# STM32F733ZET7 register map
File version: 1.0
Registers are 32-bit, access not given, reset 0x0 unless marked. A register's access mark holds for its fields unless they carry their own. Offsets are from the block's base; [hi:lo] are bit positions; {n}, {i} and the like mark numbered series; 'fields as' and 'values as' point back to an identical list.

## CRC
Base 0x40023000
0x00 DR
0x04 IDR 8-bit
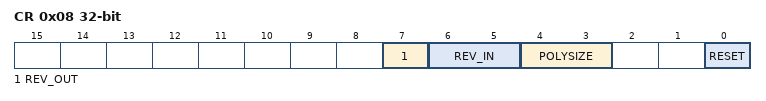
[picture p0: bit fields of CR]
0x08 CR
  [7] REV_OUT, [6:5] REV_IN, [4:3] POLYSIZE, [0] RESET
0x10 INIT
0x14 POL

## FLASH
Base 0x40023C00
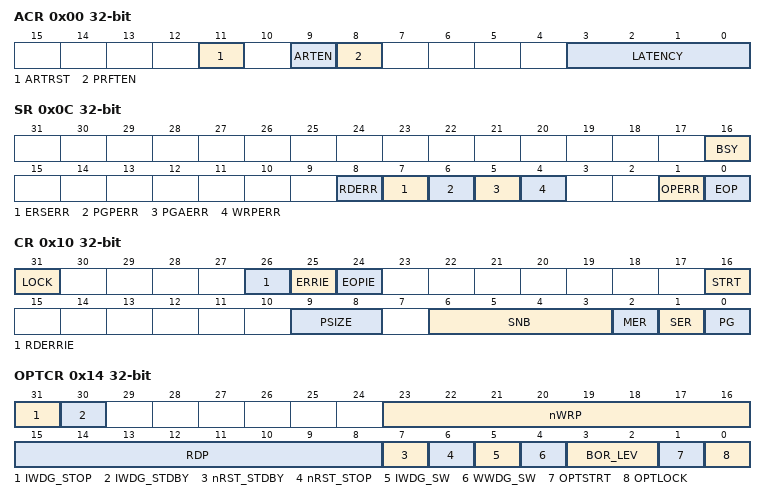
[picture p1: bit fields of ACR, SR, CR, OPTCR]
0x00 ACR
  [11] ARTRST, [9] ARTEN, [8] PRFTEN, [3:0] LATENCY
0x04 KEYR
0x08 OPTKEYR
0x0C SR
  [16] BSY, [8] RDERR, [7] ERSERR, [6] PGPERR, [5] PGAERR, [4] WRPERR, [1] OPERR, [0] EOP
0x10 CR
  [31] LOCK, [26] RDERRIE, [25] ERRIE, [24] EOPIE, [16] STRT, [9:8] PSIZE, [6:3] SNB, [2] MER, [1] SER, [0] PG
0x14 OPTCR
  [31] IWDG_STOP, [30] IWDG_STDBY, [23:16] nWRP, [15:8] RDP, [7] nRST_STDBY, [6] nRST_STOP, [5] IWDG_SW, [4] WWDG_SW, [3:2] BOR_LEV, [1] OPTSTRT, [0] OPTLOCK
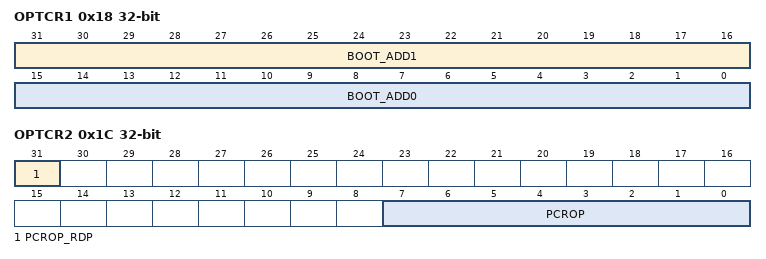
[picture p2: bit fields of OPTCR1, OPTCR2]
0x18 OPTCR1
  [31:16] BOOT_ADD1, [15:0] BOOT_ADD0
0x1C OPTCR2
  [31] PCROP_RDP, [7:0] PCROP

## DMA1
Base 0x40026000
Same registers: DMA2 0x40026400
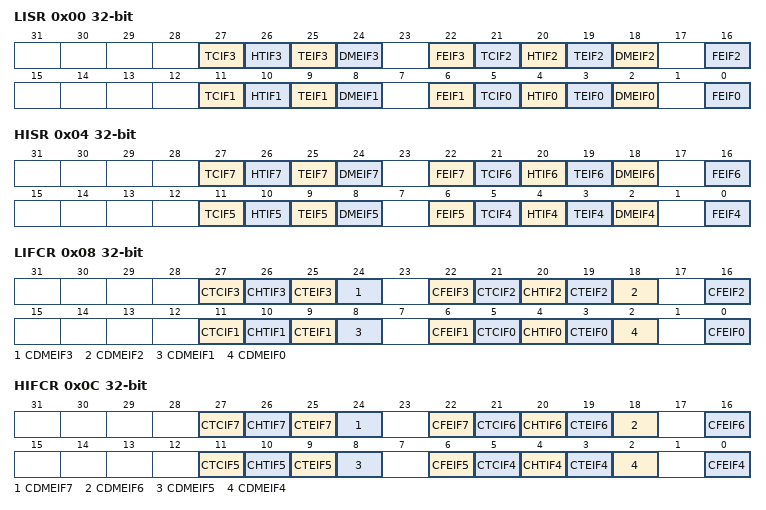
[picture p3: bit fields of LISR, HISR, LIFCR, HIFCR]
0x00 LISR
  [27] TCIF3, [26] HTIF3, [25] TEIF3, [24] DMEIF3, [22] FEIF3, [21] TCIF2, [20] HTIF2, [19] TEIF2, [18] DMEIF2, [16] FEIF2, [11] TCIF1, [10] HTIF1, [9] TEIF1, [8] DMEIF1, [6] FEIF1, [5] TCIF0, [4] HTIF0, [3] TEIF0, [2] DMEIF0, [0] FEIF0
0x04 HISR
  [27] TCIF7, [26] HTIF7, [25] TEIF7, [24] DMEIF7, [22] FEIF7, [21] TCIF6, [20] HTIF6, [19] TEIF6, [18] DMEIF6, [16] FEIF6, [11] TCIF5, [10] HTIF5, [9] TEIF5, [8] DMEIF5, [6] FEIF5, [5] TCIF4, [4] HTIF4, [3] TEIF4, [2] DMEIF4, [0] FEIF4
0x08 LIFCR
  [27] CTCIF3, [26] CHTIF3, [25] CTEIF3, [24] CDMEIF3, [22] CFEIF3, [21] CTCIF2, [20] CHTIF2, [19] CTEIF2, [18] CDMEIF2, [16] CFEIF2, [11] CTCIF1, [10] CHTIF1, [9] CTEIF1, [8] CDMEIF1, [6] CFEIF1, [5] CTCIF0, [4] CHTIF0, [3] CTEIF0, [2] CDMEIF0, [0] CFEIF0
0x0C HIFCR
  [27] CTCIF7, [26] CHTIF7, [25] CTEIF7, [24] CDMEIF7, [22] CFEIF7, [21] CTCIF6, [20] CHTIF6, [19] CTEIF6, [18] CDMEIF6, [16] CFEIF6, [11] CTCIF5, [10] CHTIF5, [9] CTEIF5, [8] CDMEIF5, [6] CFEIF5, [5] CTCIF4, [4] CHTIF4, [3] CTEIF4, [2] CDMEIF4, [0] CFEIF4
{0x10+0x18*i} CR{i} (i=0..7)
{0x14+0x18*i} NDTR{i} (i=0..7)
{0x18+0x18*i} PAR{i} (i=0..7)
{0x1C+0x18*i} M0AR{i} (i=0..7)
{0x20+0x18*i} M1AR{i} (i=0..7)
{0x24+0x18*i} FCR{i} (i=0..7)

## USB_OTG_HS
Base 0x40040000
Same registers: USB_OTG_FS 0x50000000
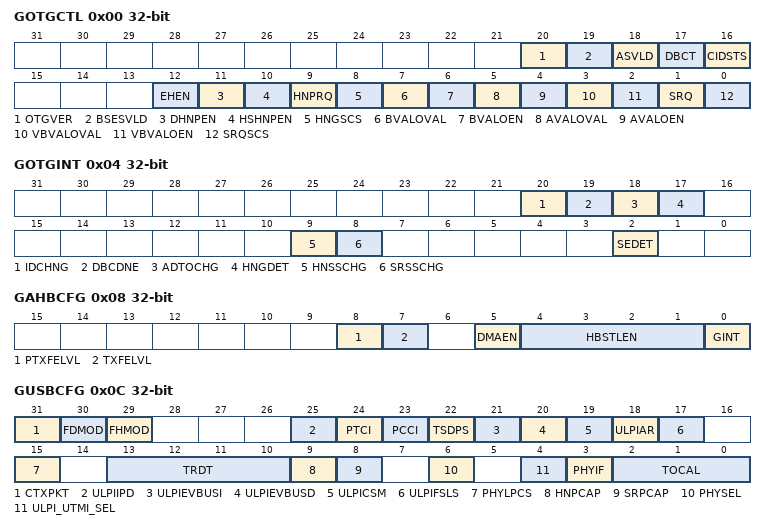
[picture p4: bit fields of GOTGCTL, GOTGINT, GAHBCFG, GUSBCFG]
0x00 GOTGCTL
  [20] OTGVER, [19] BSESVLD, [18] ASVLD, [17] DBCT, [16] CIDSTS, [12] EHEN, [11] DHNPEN, [10] HSHNPEN, [9] HNPRQ, [8] HNGSCS, [7] BVALOVAL, [6] BVALOEN, [5] AVALOVAL, [4] AVALOEN, [3] VBVALOVAL, [2] VBVALOEN, [1] SRQ, [0] SRQSCS
0x04 GOTGINT
  [20] IDCHNG, [19] DBCDNE, [18] ADTOCHG, [17] HNGDET, [9] HNSSCHG, [8] SRSSCHG, [2] SEDET
0x08 GAHBCFG
  [8] PTXFELVL, [7] TXFELVL, [5] DMAEN, [4:1] HBSTLEN, [0] GINT
0x0C GUSBCFG
  [31] CTXPKT, [30] FDMOD, [29] FHMOD, [25] ULPIIPD, [24] PTCI, [23] PCCI, [22] TSDPS, [21] ULPIEVBUSI, [20] ULPIEVBUSD, [19] ULPICSM, [18] ULPIAR, [17] ULPIFSLS, [15] PHYLPCS, [13:10] TRDT, [9] HNPCAP, [8] SRPCAP, [6] PHYSEL, [4] ULPI_UTMI_SEL, [3] PHYIF, [2:0] TOCAL
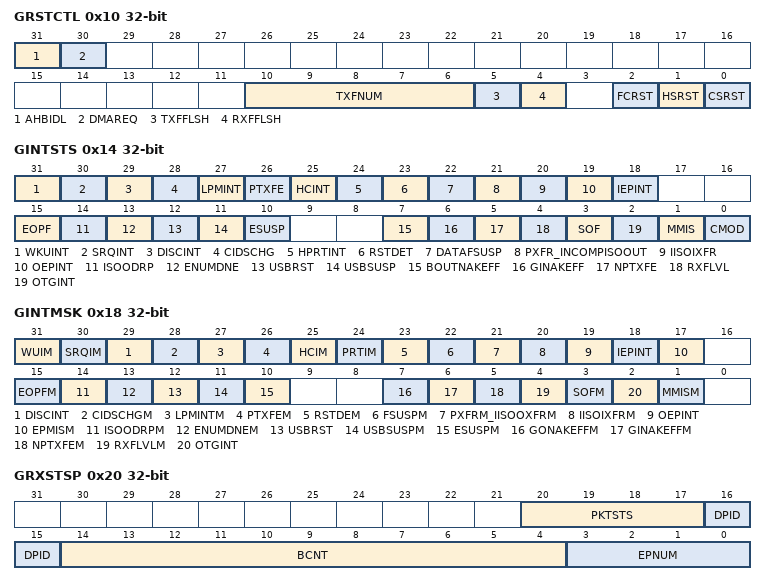
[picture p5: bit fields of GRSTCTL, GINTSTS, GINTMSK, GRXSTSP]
0x10 GRSTCTL
  [31] AHBIDL, [30] DMAREQ, [10:6] TXFNUM, [5] TXFFLSH, [4] RXFFLSH, [2] FCRST, [1] HSRST, [0] CSRST
0x14 GINTSTS
  [31] WKUINT, [30] SRQINT, [29] DISCINT, [28] CIDSCHG, [27] LPMINT, [26] PTXFE, [25] HCINT, [24] HPRTINT, [23] RSTDET, [22] DATAFSUSP, [21] PXFR_INCOMPISOOUT, [20] IISOIXFR, [19] OEPINT, [18] IEPINT, [15] EOPF, [14] ISOODRP, [13] ENUMDNE, [12] USBRST, [11] USBSUSP, [10] ESUSP, [7] BOUTNAKEFF, [6] GINAKEFF, [5] NPTXFE, [4] RXFLVL, [3] SOF, [2] OTGINT, [1] MMIS, [0] CMOD
0x18 GINTMSK
  [31] WUIM, [30] SRQIM, [29] DISCINT, [28] CIDSCHGM, [27] LPMINTM, [26] PTXFEM, [25] HCIM, [24] PRTIM, [23] RSTDEM, [22] FSUSPM, [21] PXFRM_IISOOXFRM, [20] IISOIXFRM, [19] OEPINT, [18] IEPINT, [17] EPMISM, [15] EOPFM, [14] ISOODRPM, [13] ENUMDNEM, [12] USBRST, [11] USBSUSPM, [10] ESUSPM, [7] GONAKEFFM, [6] GINAKEFFM, [5] NPTXFEM, [4] RXFLVLM, [3] SOFM, [2] OTGINT, [1] MMISM
0x1C GRXSTSR
0x20 GRXSTSP
  [20:17] PKTSTS, [16:15] DPID, [14:4] BCNT, [3:0] EPNUM
0x24 GRXFSIZ
  [15:0] RXFD
0x28 DIEPTXF0_HNPTXFSIZ
0x2C HNPTXSTS
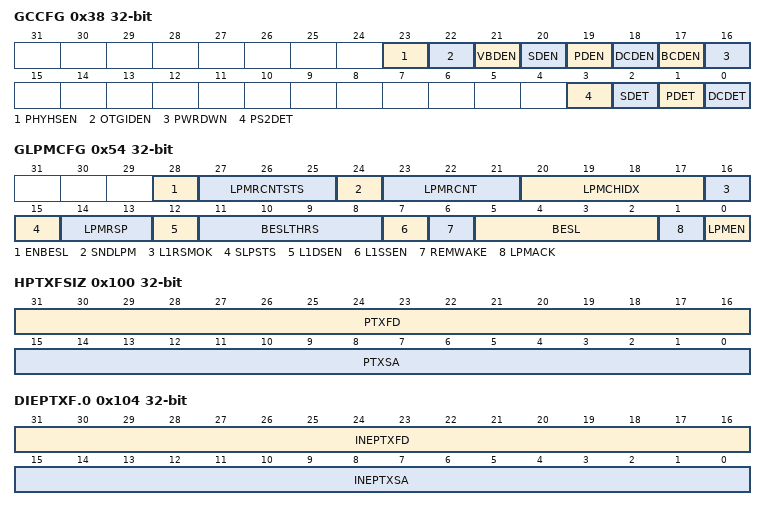
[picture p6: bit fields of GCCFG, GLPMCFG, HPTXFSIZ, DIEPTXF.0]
0x38 GCCFG
  [23] PHYHSEN, [22] OTGIDEN, [21] VBDEN, [20] SDEN, [19] PDEN, [18] DCDEN, [17] BCDEN, [16] PWRDWN, [3] PS2DET, [2] SDET, [1] PDET, [0] DCDET
0x3C CID
  [31:0] PRODUCT_ID
0x4C GHWCFG3
0x54 GLPMCFG
  [28] ENBESL, [27:25] LPMRCNTSTS, [24] SNDLPM, [23:21] LPMRCNT, [20:17] LPMCHIDX, [16] L1RSMOK, [15] SLPSTS, [14:13] LPMRSP, [12] L1DSEN, [11:8] BESLTHRS, [7] L1SSEN, [6] REMWAKE, [5:2] BESL, [1] LPMACK, [0] LPMEN
0x5C GDFIFOCFG
0x100 HPTXFSIZ
  [31:16] PTXFD, [15:0] PTXSA
0x104 DIEPTXF.0
  [31:16] INEPTXFD, [15:0] INEPTXSA
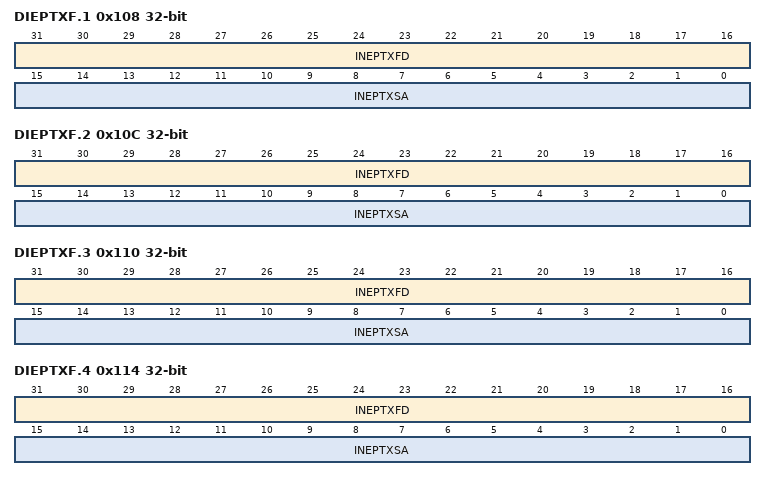
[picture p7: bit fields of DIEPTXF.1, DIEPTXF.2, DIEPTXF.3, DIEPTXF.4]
0x108 DIEPTXF.1
  [31:16] INEPTXFD, [15:0] INEPTXSA
0x10C DIEPTXF.2
  [31:16] INEPTXFD, [15:0] INEPTXSA
0x110 DIEPTXF.3
  [31:16] INEPTXFD, [15:0] INEPTXSA
0x114 DIEPTXF.4
  [31:16] INEPTXFD, [15:0] INEPTXSA
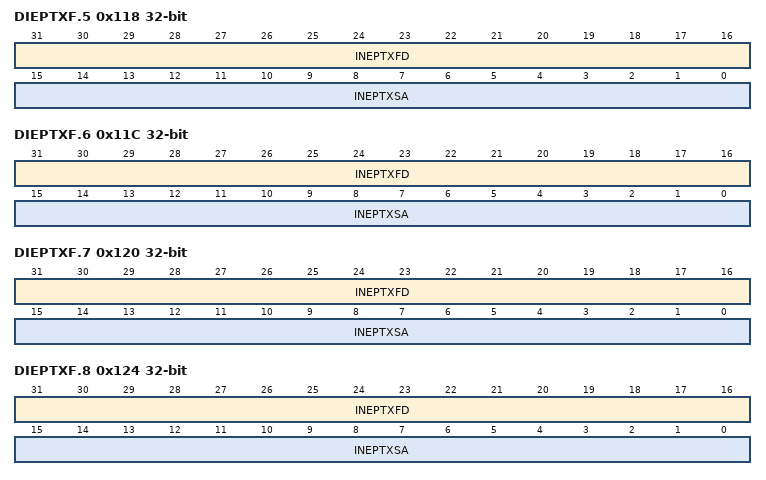
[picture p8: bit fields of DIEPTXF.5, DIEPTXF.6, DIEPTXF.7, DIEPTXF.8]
0x118 DIEPTXF.5
  [31:16] INEPTXFD, [15:0] INEPTXSA
0x11C DIEPTXF.6
  [31:16] INEPTXFD, [15:0] INEPTXSA
0x120 DIEPTXF.7
  [31:16] INEPTXFD, [15:0] INEPTXSA
0x124 DIEPTXF.8
  [31:16] INEPTXFD, [15:0] INEPTXSA
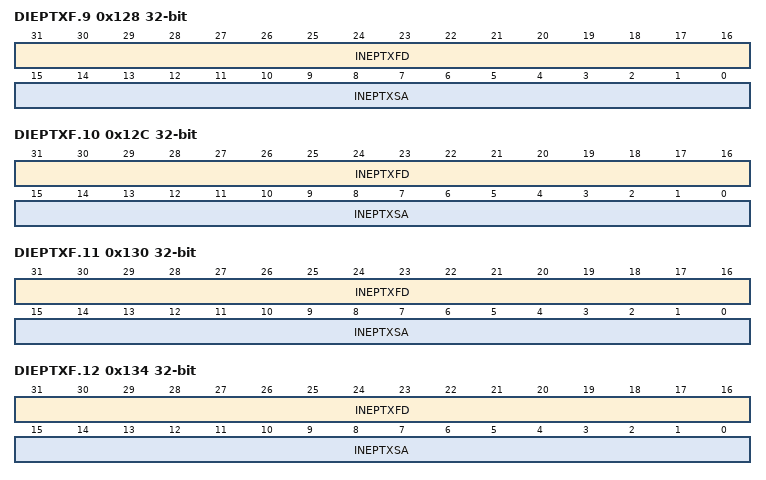
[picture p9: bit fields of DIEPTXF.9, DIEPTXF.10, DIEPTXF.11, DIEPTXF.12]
0x128 DIEPTXF.9
  [31:16] INEPTXFD, [15:0] INEPTXSA
0x12C DIEPTXF.10
  [31:16] INEPTXFD, [15:0] INEPTXSA
0x130 DIEPTXF.11
  [31:16] INEPTXFD, [15:0] INEPTXSA
0x134 DIEPTXF.12
  [31:16] INEPTXFD, [15:0] INEPTXSA
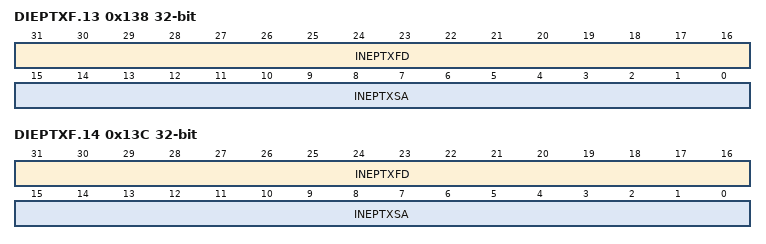
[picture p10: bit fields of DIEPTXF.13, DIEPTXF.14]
0x138 DIEPTXF.13
  [31:16] INEPTXFD, [15:0] INEPTXSA
0x13C DIEPTXF.14
  [31:16] INEPTXFD, [15:0] INEPTXSA

## AES
Base 0x50060000
0x00 CR
  [18] KEYSIZE, [14:13] GCMPH, [12] DMAOUTEN, [11] DMAINEN, [10] ERRIE, [9] CCFIE, [8] ERRC, [7] CCFC, [16:5] CHMOD, [4:3] MODE, [2:1] DATATYPE, [0] EN
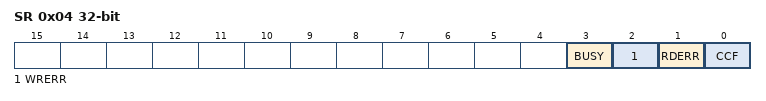
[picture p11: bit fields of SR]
0x04 SR
  [3] BUSY, [2] WRERR, [1] RDERR, [0] CCF
0x08 DINR
0x0C DOUTR
{0x10+4i} KEYR{i} (i=0..3)
{0x20+4i} IVR{i} (i=0..3)
{0x20+4i} KEYR{i} (i=4..7)
{0x40+4i} SUSP{i}R (i=0..7)

## RNG
Base 0x50060800
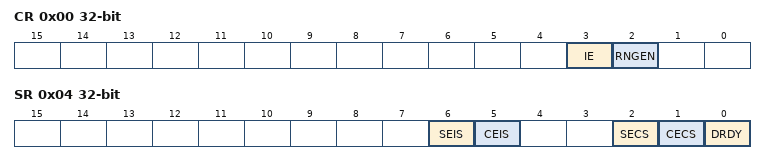
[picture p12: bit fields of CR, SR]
0x00 CR
  [3] IE, [2] RNGEN
0x04 SR
  [6] SEIS, [5] CEIS, [2] SECS, [1] CECS, [0] DRDY
0x08 DR

## FMC_Bank1
Base 0xA0000000
0x00 BTCR.0
0x04 BTCR.1
0x08 BTCR.2
0x0C BTCR.3
0x10 BTCR.4
0x14 BTCR.5
0x18 BTCR.6
0x1C BTCR.7

## FMC_Bank3
Base 0xA0000080
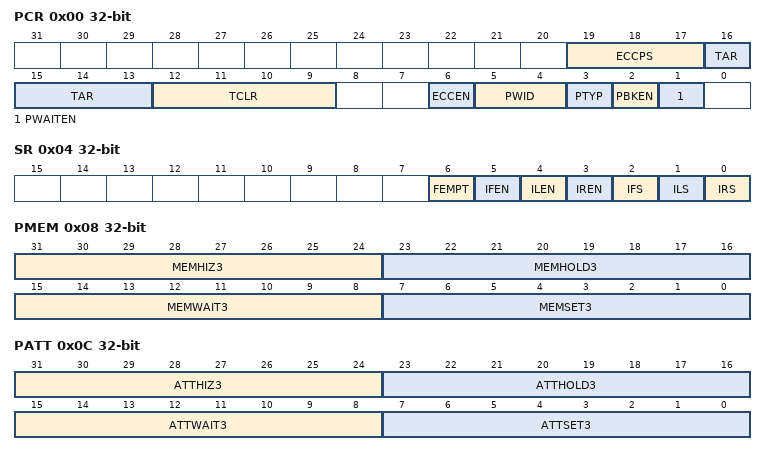
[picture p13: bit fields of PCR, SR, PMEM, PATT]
0x00 PCR
  [19:17] ECCPS, [16:13] TAR, [12:9] TCLR, [6] ECCEN, [5:4] PWID, [3] PTYP, [2] PBKEN, [1] PWAITEN
0x04 SR
  [6] FEMPT, [5] IFEN, [4] ILEN, [3] IREN, [2] IFS, [1] ILS, [0] IRS
0x08 PMEM
  [31:24] MEMHIZ3, [23:16] MEMHOLD3, [15:8] MEMWAIT3, [7:0] MEMSET3
0x0C PATT
  [31:24] ATTHIZ3, [23:16] ATTHOLD3, [15:8] ATTWAIT3, [7:0] ATTSET3
0x14 ECCR
  [31:0] ECC3

## FMC_Bank1E
Base 0xA0000104
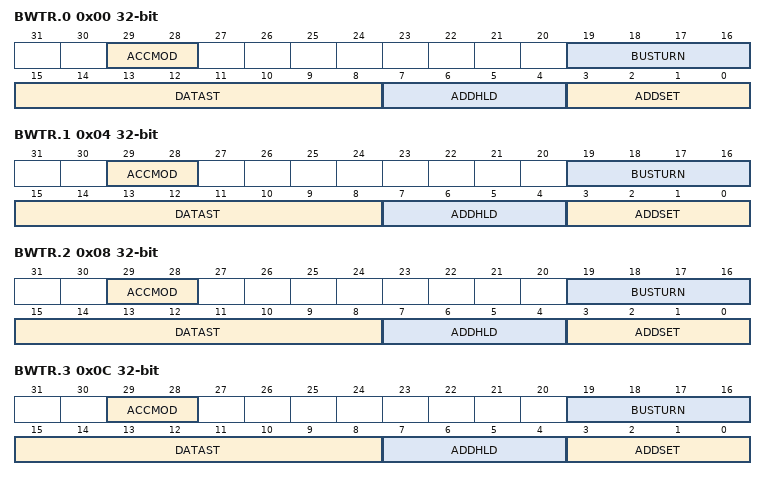
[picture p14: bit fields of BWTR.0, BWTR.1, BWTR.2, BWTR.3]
0x00 BWTR.0
  [29:28] ACCMOD, [19:16] BUSTURN, [15:8] DATAST, [7:4] ADDHLD, [3:0] ADDSET
0x04 BWTR.1
  fields as BWTR.0
0x08 BWTR.2
  fields as BWTR.0
0x0C BWTR.3
  fields as BWTR.0
0x10 BWTR.4
0x14 BWTR.5
0x18 BWTR.6

## FMC_Bank5_6
Base 0xA0000140
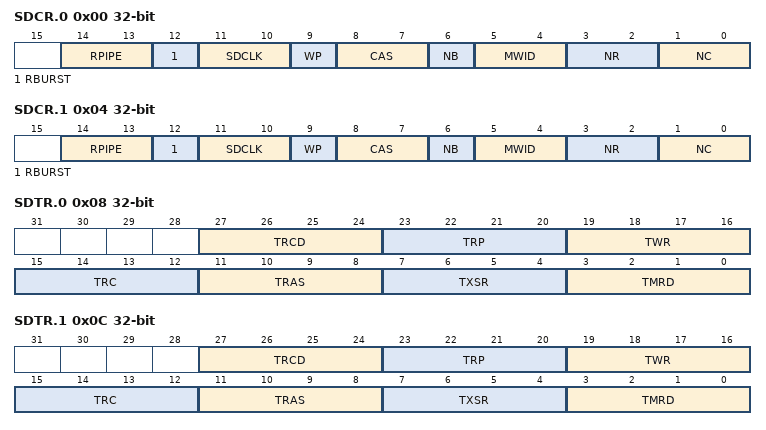
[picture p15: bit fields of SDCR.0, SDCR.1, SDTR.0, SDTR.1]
0x00 SDCR.0
  [14:13] RPIPE, [12] RBURST, [11:10] SDCLK, [9] WP, [8:7] CAS, [6] NB, [5:4] MWID, [3:2] NR, [1:0] NC
0x04 SDCR.1
  fields as SDCR.0
0x08 SDTR.0
  [27:24] TRCD, [23:20] TRP, [19:16] TWR, [15:12] TRC, [11:8] TRAS, [7:4] TXSR, [3:0] TMRD
0x0C SDTR.1
  fields as SDTR.0
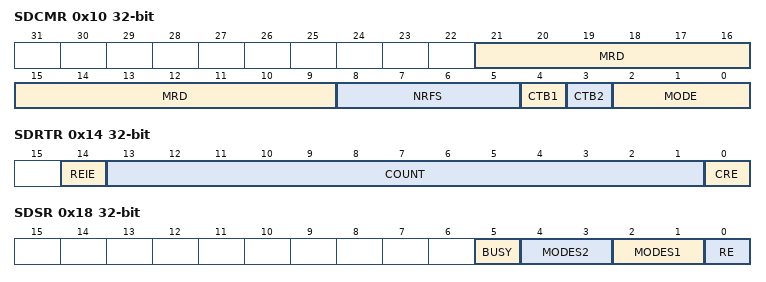
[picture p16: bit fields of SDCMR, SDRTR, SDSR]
0x10 SDCMR
  [21:9] MRD, [8:5] NRFS, [4] CTB1, [3] CTB2, [2:0] MODE
0x14 SDRTR
  [14] REIE, [13:1] COUNT, [0] CRE
0x18 SDSR
  [5] BUSY, [4:3] MODES2, [2:1] MODES1, [0] RE

## QUADSPI
Base 0xA0001000
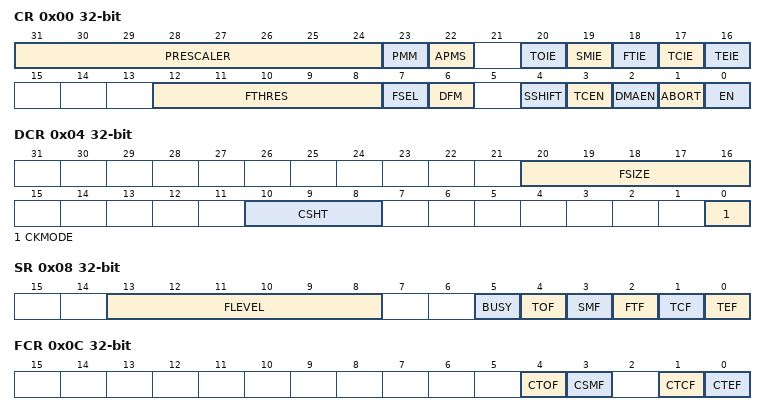
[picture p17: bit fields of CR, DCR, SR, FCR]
0x00 CR
  [31:24] PRESCALER, [23] PMM, [22] APMS, [20] TOIE, [19] SMIE, [18] FTIE, [17] TCIE, [16] TEIE, [12:8] FTHRES, [7] FSEL, [6] DFM, [4] SSHIFT, [3] TCEN, [2] DMAEN, [1] ABORT, [0] EN
0x04 DCR
  [20:16] FSIZE, [10:8] CSHT, [0] CKMODE
0x08 SR
  [13:8] FLEVEL, [5] BUSY, [4] TOF, [3] SMF, [2] FTF, [1] TCF, [0] TEF
0x0C FCR
  [4] CTOF, [3] CSMF, [1] CTCF, [0] CTEF
0x10 DLR
  [31:0] DL
0x14 CCR
  [31] DDRM, [30] DHHC, [28] SIOO, [27:26] FMODE, [25:24] DMODE, [22:18] DCYC, [17:16] ABSIZE, [15:14] ABMODE, [13:12] ADSIZE, [11:10] ADMODE, [9:8] IMODE, [7:0] INSTRUCTION
0x18 AR
  [31:0] ADDRESS
0x1C ABR
  [31:0] ALTERNATE
0x20 DR
  [31:0] DATA
0x24 PSMKR
  [31:0] MASK
0x28 PSMAR
  [31:0] MATCH
0x2C PIR
  [15:0] INTERVAL
0x30 LPTR
  [15:0] TIMEOUT

## DBGMCU
Base 0xE0042000
0x00 IDCODE
  [31:16] REV_ID, [11:0] DEV_ID
0x04 CR
  [7:6] TRACE_MODE, [5] TRACE_IOEN, [2] DBG_STANDBY, [1] DBG_STOP, [0] DBG_SLEEP
0x08 APB1FZ
  [25] DBG_CAN1_STOP, [23] DBG_I2C3_SMBUS_TIMEOUT, [22] DBG_I2C2_SMBUS_TIMEOUT, [21] DBG_I2C1_SMBUS_TIMEOUT, [12] DBG_IWDG_STOP, [11] DBG_WWDG_STOP, [10] DBG_RTC_STOP, [9] DBG_LPTIM1_STOP, [8] DBG_TIM14_STOP, [7] DBG_TIM13_STOP, [6] DBG_TIM12_STOP, [n-2] DBG_TIM{n}_STOP (n=2..7)
0x0C APB2FZ
  [18] DBG_TIM11_STOP, [17] DBG_TIM10_STOP, [16] DBG_TIM9_STOP, [1] DBG_TIM8_STOP, [0] DBG_TIM1_STOP
